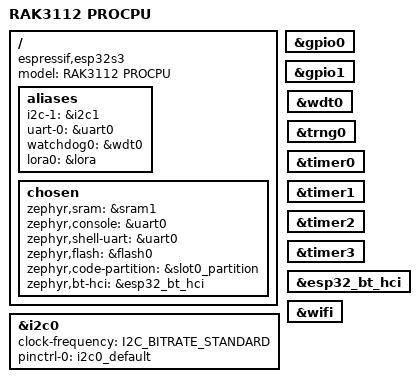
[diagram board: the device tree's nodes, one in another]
/*
 * Copyright (c) 2025 Kenneth Lu
 * SPDX-License-Identifier: Apache-2.0
 */

/dts-v1/;
#include <rakwireless/rak3112.dtsi>
#include "rak3112-pinctrl.dtsi"
#include <zephyr/dt-bindings/input/input-event-codes.h>
#include <espressif/partitions_0x0_amp_16M.dtsi>

/ {
	model = "RAK3112 PROCPU";
	compatible = "espressif,esp32s3";

	aliases {
		i2c-1 = &i2c1;
		uart-0 = &uart0;
		watchdog0 = &wdt0;
		lora0 = &lora;
	};

	chosen {
		zephyr,sram = &sram1;
		zephyr,console = &uart0;
		zephyr,shell-uart = &uart0;
		zephyr,flash = &flash0;
		zephyr,code-partition = &slot0_partition;
		zephyr,bt-hci = &esp32_bt_hci;
	};
};

&gpio0 {
	status = "okay";
};

&gpio1 {
	status = "okay";
};

&i2c0 {
	clock-frequency = <I2C_BITRATE_STANDARD>;
	pinctrl-0 = <&i2c0_default>;
	pinctrl-names = "default";
};

&wdt0 {
	status = "okay";
};

&trng0 {
	status = "okay";
};

&timer0 {
	status = "okay";
};

&timer1 {
	status = "okay";
};

&timer2 {
	status = "okay";
};

&timer3 {
	status = "okay";
};

&esp32_bt_hci {
	status = "okay";
};

&wifi {
	status = "okay";
};
